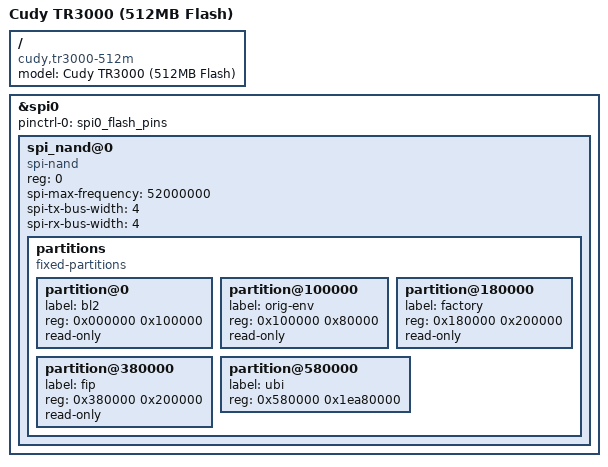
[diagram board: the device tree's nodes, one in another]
// SPDX-License-Identifier: (GPL-2.0 OR MIT)

/dts-v1/;
#include "mt7981b-cudy-tr3000.dts"

/ {
	model = "Cudy TR3000 (512MB Flash)";
	compatible = "cudy,tr3000-512m", "cudy,tr3000", "mediatek,mt7981";
};

&spi0 {
	pinctrl-names = "default";
	pinctrl-0 = <&spi0_flash_pins>;
	status = "okay";

	spi_nand@0 {
		compatible = "spi-nand";
		#address-cells = <1>;
		#size-cells = <1>;
		reg = <0>;

		spi-max-frequency = <52000000>;
		spi-tx-bus-width = <4>;
		spi-rx-bus-width = <4>;

		partitions {
			compatible = "fixed-partitions";
			#address-cells = <1>;
			#size-cells = <1>;

			partition@0 {
				label = "bl2";
				reg = <0x000000 0x100000>;
				read-only;
			};

			partition@100000 {
				label = "orig-env";
				reg = <0x100000 0x80000>;
				read-only;
			};

			partition@180000 {
				label = "factory";
				reg = <0x180000 0x200000>;
				read-only;
			};

			partition@380000 {
				label = "fip";
				reg = <0x380000 0x200000>;
				read-only;
			};

			partition@580000 {
				label = "ubi";
				reg = <0x580000 0x1ea80000>;
			};
		};
	};
};
